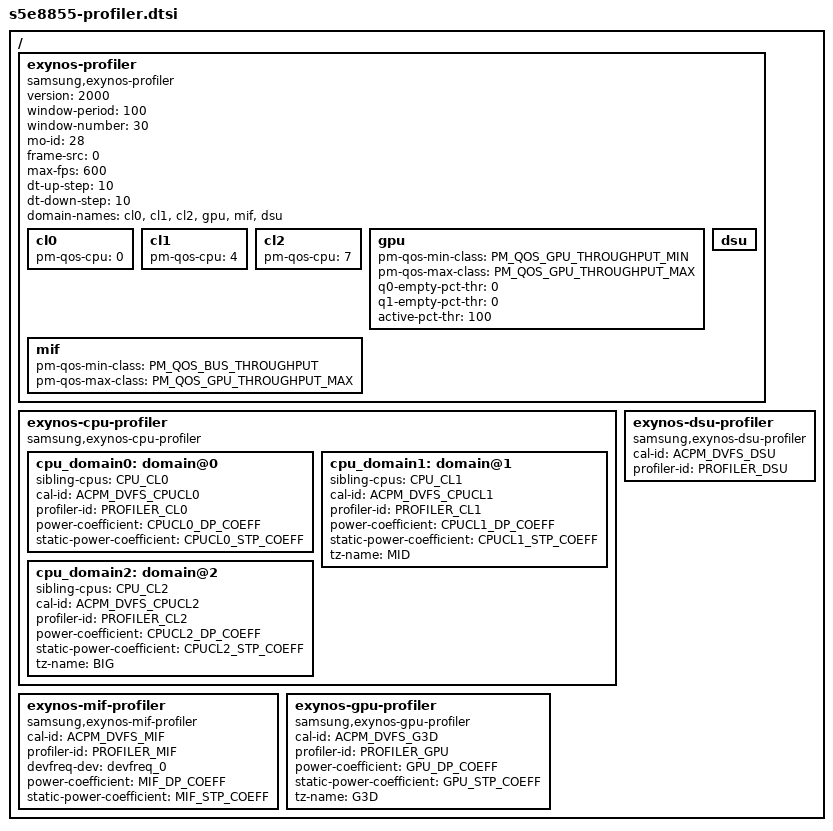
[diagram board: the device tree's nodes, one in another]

/*
 * SAMSUNG PROFILER device tree source
 *
 * Copyright (c) 2020 Samsung Electronics Co., Ltd.
 *		http://www.samsung.com
 *
 * This program is free software; you can redistribute it and/or modify
 * it under the terms of the GNU General Public License version 2 as
 * published by the Free Software Foundation.
 */

#include <dt-bindings/soc/samsung/s5e8855-profiler-dt.h>

/{
	exynos-profiler {
		compatible = "samsung,exynos-profiler";
		status = "okay";

		/* Common */
		version = < 2000 >;
		window-period = < 100 >;
		window-number = < 30 >;
		mo-id = < 28 > ;

		/* FPS */
		frame-src = < 0 >;      /* 0: use frame-done, 1: use frame-done and  missed-frame */
		max-fps = < 600 >;
		dt-up-step = < 10 >;
		dt-down-step =  < 10 >;

		/* domain list */
		domain-names = "cl0", "cl1", "cl2", "gpu", "mif", "dsu";

		cl0 {
			pm-qos-cpu = < 0 >;
		};
		cl1 {
			pm-qos-cpu = < 4 >;
		};
		cl2 {
			pm-qos-cpu = < 7 >;
		};
		gpu {
			pm-qos-min-class = < PM_QOS_GPU_THROUGHPUT_MIN >;
			pm-qos-max-class = < PM_QOS_GPU_THROUGHPUT_MAX >;
			q0-empty-pct-thr = < 0 >;
			q1-empty-pct-thr = < 0 >;
			active-pct-thr = < 100 >;
		};
		mif {
			pm-qos-min-class = < PM_QOS_BUS_THROUGHPUT >;
			pm-qos-max-class = < PM_QOS_GPU_THROUGHPUT_MAX >;
		};
		dsu {
		};
	};

	exynos-cpu-profiler {
		compatible = "samsung,exynos-cpu-profiler";
		status = "okay";

		#define CPU_CL0		"0-3"
		#define CPU_CL1		"4-6"
		#define CPU_CL2		"7"
		#define CPU_ALL		"0-7"


		#define CPUCL0_DP_COEFF		146
		#define CPUCL0_STP_COEFF	62
		#define CPUCL1_DP_COEFF		394
		#define CPUCL1_STP_COEFF	234
		#define CPUCL2_DP_COEFF		394
		#define CPUCL2_STP_COEFF	537

		#define GPU_DP_COEFF		13360
		#define GPU_STP_COEFF		400
		#define MIF_DP_COEFF		70110000
		#define MIF_STP_COEFF		535

		cpu_domain0: domain@0 {
		     /* necessary data */
		     sibling-cpus = CPU_CL0;
		     cal-id = <ACPM_DVFS_CPUCL0>;

			 profiler-id = <PROFILER_CL0>;
			 power-coefficient = <CPUCL0_DP_COEFF>;
			 static-power-coefficient = <CPUCL0_STP_COEFF>;
		};
		cpu_domain1: domain@1 {
		     /* necessary data */
		     sibling-cpus = CPU_CL1;
		     cal-id = <ACPM_DVFS_CPUCL1>;

		     profiler-id = <PROFILER_CL1>;
			 power-coefficient = <CPUCL1_DP_COEFF>;
			 static-power-coefficient = <CPUCL1_STP_COEFF>;
		     tz-name = "MID";
		};
		cpu_domain2: domain@2 {
		     /* necessary data */
		     sibling-cpus = CPU_CL2;
		     cal-id = <ACPM_DVFS_CPUCL2>;

		     profiler-id = <PROFILER_CL2>;
			 power-coefficient = <CPUCL2_DP_COEFF>;
			 static-power-coefficient = <CPUCL2_STP_COEFF>;
		     tz-name = "BIG";
		};
	};

	exynos-mif-profiler {
		compatible = "samsung,exynos-mif-profiler";
		status = "okay";

		cal-id = <ACPM_DVFS_MIF>;

		profiler-id = <PROFILER_MIF>;
		devfreq-dev = <&devfreq_0>;
		power-coefficient = <MIF_DP_COEFF>;
		static-power-coefficient = <MIF_STP_COEFF>;
	};

	exynos-gpu-profiler {
		compatible = "samsung,exynos-gpu-profiler";
		status = "okay";

		cal-id = <ACPM_DVFS_G3D>;

		profiler-id = <PROFILER_GPU>;
		power-coefficient = <GPU_DP_COEFF>;
		static-power-coefficient = <GPU_STP_COEFF>;
		tz-name = "G3D";
	};

	exynos-dsu-profiler {
		compatible = "samsung,exynos-dsu-profiler";
		status = "okay";

		cal-id = <ACPM_DVFS_DSU>;

		profiler-id = <PROFILER_DSU>;
	};
};
